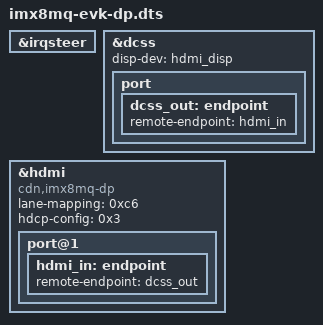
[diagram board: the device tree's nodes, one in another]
// SPDX-License-Identifier: GPL-2.0
/*
 * Copyright 2019 NXP.
 */

#include "imx8mq-evk.dts"

&irqsteer {
	status = "okay";
};

&dcss {
	status = "okay";
	disp-dev = "hdmi_disp";

	port {
		dcss_out: endpoint {
			remote-endpoint = <&hdmi_in>;
		};
	};
};

&hdmi {
	compatible = "cdn,imx8mq-dp";
	lane-mapping = <0xc6>;
	hdcp-config = <0x3>;
	status = "okay";

	port@1 {
		hdmi_in: endpoint {
			remote-endpoint = <&dcss_out>;
		};
	};
};
